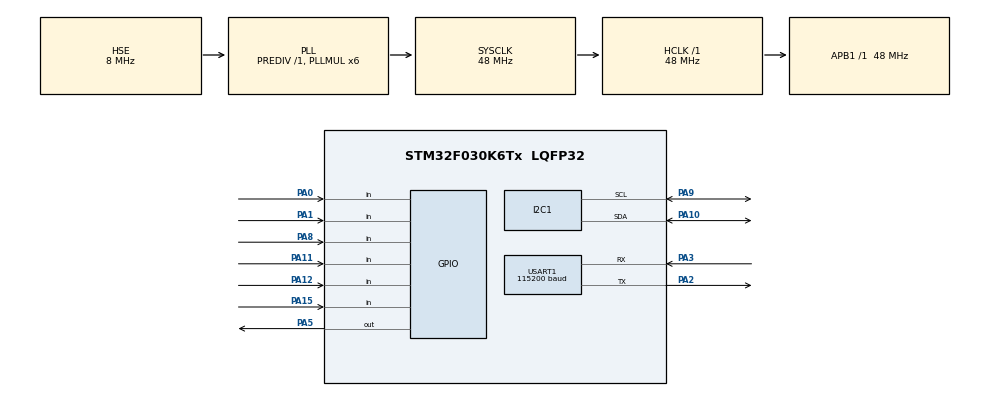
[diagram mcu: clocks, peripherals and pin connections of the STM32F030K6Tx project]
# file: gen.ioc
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Dma.I2C1_RX.2.Direction=DMA_PERIPH_TO_MEMORY
Dma.I2C1_RX.2.Instance=DMA1_Channel3
Dma.I2C1_RX.2.MemDataAlignment=DMA_MDATAALIGN_BYTE
Dma.I2C1_RX.2.MemInc=DMA_MINC_ENABLE
Dma.I2C1_RX.2.Mode=DMA_NORMAL
Dma.I2C1_RX.2.PeriphDataAlignment=DMA_PDATAALIGN_BYTE
Dma.I2C1_RX.2.PeriphInc=DMA_PINC_DISABLE
Dma.I2C1_RX.2.Priority=DMA_PRIORITY_LOW
Dma.I2C1_TX.3.Direction=DMA_MEMORY_TO_PERIPH
Dma.I2C1_TX.3.Instance=DMA1_Channel2
Dma.I2C1_TX.3.MemDataAlignment=DMA_MDATAALIGN_BYTE
Dma.I2C1_TX.3.MemInc=DMA_MINC_ENABLE
Dma.I2C1_TX.3.Mode=DMA_NORMAL
Dma.I2C1_TX.3.PeriphDataAlignment=DMA_PDATAALIGN_BYTE
Dma.I2C1_TX.3.PeriphInc=DMA_PINC_DISABLE
Dma.I2C1_TX.3.Priority=DMA_PRIORITY_LOW
Dma.Request0=USART1_RX
Dma.Request1=USART1_TX
Dma.Request2=I2C1_RX
Dma.Request3=I2C1_TX
Dma.USART1_RX.0.Direction=DMA_PERIPH_TO_MEMORY
Dma.USART1_RX.0.Instance=DMA1_Channel5
Dma.USART1_RX.0.MemDataAlignment=DMA_MDATAALIGN_BYTE
Dma.USART1_RX.0.MemInc=DMA_MINC_ENABLE
Dma.USART1_RX.0.Mode=DMA_CIRCULAR
Dma.USART1_RX.0.PeriphDataAlignment=DMA_PDATAALIGN_BYTE
Dma.USART1_RX.0.PeriphInc=DMA_PINC_DISABLE
Dma.USART1_RX.0.Priority=DMA_PRIORITY_LOW
Dma.USART1_TX.1.Direction=DMA_MEMORY_TO_PERIPH
Dma.USART1_TX.1.Instance=DMA1_Channel4
Dma.USART1_TX.1.MemDataAlignment=DMA_MDATAALIGN_BYTE
Dma.USART1_TX.1.MemInc=DMA_MINC_ENABLE
Dma.USART1_TX.1.Mode=DMA_NORMAL
Dma.USART1_TX.1.PeriphDataAlignment=DMA_PDATAALIGN_BYTE
Dma.USART1_TX.1.PeriphInc=DMA_PINC_DISABLE
Dma.USART1_TX.1.Priority=DMA_PRIORITY_LOW
Mcu.Family=STM32F0
Mcu.Name=STM32F030K6Tx
Mcu.Package=LQFP32
NVIC.DMA1_Channel2_3_IRQn=true\:0\:0\:false\:false\:true\:false\:true
NVIC.DMA1_Channel4_5_IRQn=true\:0\:0\:false\:false\:true\:false\:true
NVIC.I2C1_IRQn=true\:0\:0\:false\:false\:true\:true\:true
NVIC.TIM1_BRK_UP_TRG_COM_IRQn=true\:0\:0\:false\:false\:true\:false\:true
NVIC.TimeBase=TIM1_BRK_UP_TRG_COM_IRQn
NVIC.TimeBaseIP=TIM1
NVIC.USART1_IRQn=true\:0\:0\:false\:false\:true\:true\:true
PA0.Signal=GPIO_Input
PA1.Signal=GPIO_Input
PA10.GPIO_PuPdOD=GPIO_PULLUP
PA10.Mode=I2C
PA10.Signal=I2C1_SDA
PA11.Signal=GPIO_Input
PA12.Signal=GPIO_Input
PA13.Mode=Serial_Wire
PA13.Signal=SYS_SWDIO
PA14.Mode=Serial_Wire
PA14.Signal=SYS_SWCLK
PA15.Signal=GPIO_Input
PA2.Mode=Asynchronous
PA2.Signal=USART1_TX
PA3.Mode=Asynchronous
PA3.Signal=USART1_RX
PA5.Signal=GPIO_Output
PA8.Signal=GPIO_Input
PA9.GPIO_PuPdOD=GPIO_PULLUP
PA9.Mode=I2C
PA9.Signal=I2C1_SCL
PF0-OSC_IN.Mode=HSE-External-Oscillator
PF0-OSC_IN.Signal=RCC_OSC_IN
PF1-OSC_OUT.Mode=HSE-External-Oscillator
PF1-OSC_OUT.Signal=RCC_OSC_OUT
ProjectManager.HeapSize=0x200
ProjectManager.StackSize=0x400
ProjectManager.TargetToolchain=SW4STM32
RCC.AHBFreq_Value=48000000
RCC.APB1Freq_Value=48000000
RCC.APB1TimFreq_Value=48000000
RCC.HCLKFreq_Value=48000000
RCC.PLLMUL=RCC_PLL_MUL6
RCC.PLLSourceVirtual=RCC_PLLSOURCE_HSE
RCC.SYSCLKFreq_VALUE=48000000
RCC.SYSCLKSource=RCC_SYSCLKSOURCE_PLLCLK
USART1.BaudRate=115200
USART1.VirtualMode-Asynchronous=VM_ASYNC
VP_SYS_VS_tim1.Mode=TIM1
board=custom

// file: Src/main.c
/* USER CODE BEGIN Header */
/**
  ******************************************************************************
  * @file           : main.c
  * @brief          : Main program body
  ******************************************************************************
  * @attention
  *
  * <h2><center>&copy; Copyright (c) 2020 STMicroelectronics.
  * All rights reserved.</center></h2>
  *
  * This software component is licensed by ST under BSD 3-Clause license,
  * the "License"; You may not use this file except in compliance with the
  * License. You may obtain a copy of the License at:
  *                        opensource.org/licenses/BSD-3-Clause
  *
  ******************************************************************************
  */
/* USER CODE END Header */

#include "main.h"
#include "dma.h"
#include "i2c.h"
#include "usart.h"
#include "gpio.h"

/* USER CODE BEGIN Includes */
#include <system_init.h>
/* USER CODE END Includes */

void SystemClock_Config(void);
/* USER CODE BEGIN PFP */
extern void run(void);
/* USER CODE END PFP */

int main(void)
{

  /* MCU Configuration--------------------------------------------------------*/

  /* Reset of all peripherals, Initializes the Flash interface and the Systick. */
  HAL_Init();

  /* Configure the system clock */
  SystemClock_Config();

  /* USER CODE BEGIN SysInit */
  system_init();
  /* USER CODE END SysInit */

  /* Initialize all configured peripherals */
  MX_GPIO_Init();
  MX_DMA_Init();
  MX_I2C1_Init();
  MX_USART1_UART_Init();

  /* Infinite loop */
  /* USER CODE BEGIN WHILE */
  run();
    /* USER CODE END WHILE */

}

void SystemClock_Config(void)
{
  RCC_OscInitTypeDef RCC_OscInitStruct = {0};
  RCC_ClkInitTypeDef RCC_ClkInitStruct = {0};
  RCC_PeriphCLKInitTypeDef PeriphClkInit = {0};

  /** Initializes the CPU, AHB and APB busses clocks
  */
  RCC_OscInitStruct.OscillatorType = RCC_OSCILLATORTYPE_HSI|RCC_OSCILLATORTYPE_HSE;
  RCC_OscInitStruct.HSEState = RCC_HSE_ON;
  RCC_OscInitStruct.HSIState = RCC_HSI_ON;
  RCC_OscInitStruct.HSICalibrationValue = RCC_HSICALIBRATION_DEFAULT;
  RCC_OscInitStruct.PLL.PLLState = RCC_PLL_ON;
  RCC_OscInitStruct.PLL.PLLSource = RCC_PLLSOURCE_HSE;
  RCC_OscInitStruct.PLL.PLLMUL = RCC_PLL_MUL6;
  RCC_OscInitStruct.PLL.PREDIV = RCC_PREDIV_DIV1;
  if (HAL_RCC_OscConfig(&RCC_OscInitStruct) != HAL_OK)
  {
    Error_Handler();
  }
  /** Initializes the CPU, AHB and APB busses clocks
  */
  RCC_ClkInitStruct.ClockType = RCC_CLOCKTYPE_HCLK|RCC_CLOCKTYPE_SYSCLK
                              |RCC_CLOCKTYPE_PCLK1;
  RCC_ClkInitStruct.SYSCLKSource = RCC_SYSCLKSOURCE_PLLCLK;
  RCC_ClkInitStruct.AHBCLKDivider = RCC_SYSCLK_DIV1;
  RCC_ClkInitStruct.APB1CLKDivider = RCC_HCLK_DIV1;

  if (HAL_RCC_ClockConfig(&RCC_ClkInitStruct, FLASH_LATENCY_1) != HAL_OK)
  {
    Error_Handler();
  }
  PeriphClkInit.PeriphClockSelection = RCC_PERIPHCLK_USART1|RCC_PERIPHCLK_I2C1;
  PeriphClkInit.Usart1ClockSelection = RCC_USART1CLKSOURCE_PCLK1;
  PeriphClkInit.I2c1ClockSelection = RCC_I2C1CLKSOURCE_HSI;
  if (HAL_RCCEx_PeriphCLKConfig(&PeriphClkInit) != HAL_OK)
  {
    Error_Handler();
  }
}

void HAL_TIM_PeriodElapsedCallback(TIM_HandleTypeDef *htim)
{
  if (htim->Instance == TIM1) {
    HAL_IncTick();
  }
}

void Error_Handler(void)
{
  __disable_irq();
  while (1) {}
}

/************************ (C) COPYRIGHT STMicroelectronics *****END OF FILE****/
